VERSION ""

NS_ :

BS_:

BU_: VCU

VAL_TABLE_ RollingCounter_0x132 15 "Invalid";
VAL_TABLE_ ESC_HSA_Control_Status 1 "active" 0 "inactive";
VAL_TABLE_ ESC_HSA_Status_Fault 1 " HSA Defective" 0 "HSA Normale";
VAL_TABLE_ ESC_TcsDisableSts 3 "signal invalid" 2 "reservred" 1 "disabled" 0 "enabled";
VAL_TABLE_ ESC_TcsCtrlActv 1 "active" 0 "inactive";
VAL_TABLE_ ESC_TcsFlgFlt 1 "failure" 0 "no failure";
VAL_TABLE_ ESC_EscDisableSts 1 "disabled" 0 "enabled";
VAL_TABLE_ ESC_EscCtrlActv 1 "active" 0 "inactive";
VAL_TABLE_ ESC_EscFlgFlt 1 "failure" 0 "no failure";
VAL_TABLE_ ESC_HBAFlgFlt 1 "failure" 0 "no failure";
VAL_TABLE_ ESC_HbaCtrlActv 1 "active" 0 "inactive";
VAL_TABLE_ ESC_SlopeGradeAngle 255 "Invalid";
VAL_TABLE_ ESC_MasterCylinderPressure 4095 "Invalid";
VAL_TABLE_ RollingCounter_0x142 15 "Invalid";
VAL_TABLE_ AbsDiagSessionLampReq_Reserved 1 "lamp on" 0 "lamp off";
VAL_TABLE_ ABS_AbsCtrlActv 1 "active" 0 "inactive";
VAL_TABLE_ ABS_EbdFlgFlt 1 "failure" 0 "no failure";
VAL_TABLE_ ABS_AbsFlgFlt 1 "failure" 0 "no failure";
VAL_TABLE_ ABS_ESS_Active 1 "active" 0 "inactive";
VAL_TABLE_ ABS_LowBrakeFluid 1 "failure" 0 "no failure";
VAL_TABLE_ RollingCounter_0x332 15 "Invalid";
VAL_TABLE_ ABS_LFWhlSpdRaw 32767 "Invalid";
VAL_TABLE_ ABS_LFWhlSpdRawValid 1 "Valid" 0 "Invalid";
VAL_TABLE_ ABS_RFWhlSpdRaw 32767 "Invalid";
VAL_TABLE_ ABS_RFWhlSpdRawValid 1 "Valid" 0 "Invalid";
VAL_TABLE_ RollingCounter_0x342 15 "Invalid";
VAL_TABLE_ ABS_LRWhlSpdRaw 32767 "Invalid";
VAL_TABLE_ ABS_LRWhlSpdRawValid 1 "Valid" 0 "Invalid";
VAL_TABLE_ ABS_RRWhlSpdRaw 32767 "Invalid";
VAL_TABLE_ ABS_RRWhlSpdRawValid 1 "Valid" 0 "Invalid";
VAL_TABLE_ ABS_VehSpd 32767 "Invalid";
VAL_TABLE_ ABS_VehSpdValid 1 "Valid" 0 "Invalid";
VAL_TABLE_ RollingCounter_362 15 "Invalid";
VAL_TABLE_ ESC_RegenDragCtrlStatus 1 "active" 0 "inactive";
VAL_TABLE_ ESC_RegenBrakeCtrlStatus 1 "active" 0 "inactive";
VAL_TABLE_ ESC_TorqReqMode 3 "Reserved" 2 "Regen mode" 1 "TCS mode" 0 "Normal mode";
VAL_TABLE_ ESC_TorqRequestVal 65535 "Invalid";
VAL_TABLE_ Rolling_counter_0x37E 15 "Invalid";
VAL_TABLE_ EPS_SteeringTorque 4095 "Invalid";
VAL_TABLE_ EPS_TorqSensorStatus 1 "Invalid" 0 "Valid";
VAL_TABLE_ EPS_EpsFailed 1 "failed" 0 "not failed";
VAL_TABLE_ EPS_Mode 3 " Invalid" 1 "low assist" 0 "full assist";
VAL_TABLE_ RollingCounter_0x108 15 "Invalid";
VAL_TABLE_ EKS_DriveModeReq_reserved 1 "press" 0 "no press";
VAL_TABLE_ EKS_TargetGearReq 7 "Reserved" 4 "Invalid" 3 "D" 2 "N" 1 "R" 0 "P reserved";
VAL_TABLE_ EKS_Fault 5 "Received Date from VCU is invalid" 4 "Supply voltage failure" 3 "Position sensor failure" 2 "CAN communication fail" 1 "Shifter failure" 0 "normal";
VAL_TABLE_ RollingCounter_0x269 15 "Invalid";
VAL_TABLE_ VCU_VehicleHVStatus 3 "Reserved" 2 "ReadyToDrive" 1 "HV On" 0 "Not ready";
VAL_TABLE_ VCU_ActualGear 7 "Fault" 6 "Reserved" 5 "Reserved" 4 "Reserved" 3 "D" 2 "N" 1 "R" 0 "P reserved";
VAL_TABLE_ VCU_ActualGearValid 1 "Invalid" 0 "Valid";
VAL_TABLE_ VCU_AccPedalPosition 255 "Invalid";
VAL_TABLE_ VCU_AccPedalPositionValid 1 "Invalid" 0 "Valid";
VAL_TABLE_ VCU_TqReductionRqstResponse 1 "active" 0 "inactive";
VAL_TABLE_ VCU_BrakePedalSts 3 "Invalid" 2 "Reserved" 1 "pressed" 0 "Not pressed";
VAL_TABLE_ Rolling_Counter_0x20C 15 "Invalid";
VAL_TABLE_ IPC_ODO 1048575 "Invalid";
VAL_TABLE_ RollingCounter_0x85 15 "Invalid";
VAL_TABLE_ ACM_Crash_Sts 3 "Invalid Value" 2 "Invalid Value" 1 "Crash_Detected" 0 "No_Event";
VAL_TABLE_ ACM_Airbag_Deployment_Status 3 "Invalid Value" 2 "Invalid Value" 1 "Airbag_Deployment" 0 "No_Airbag_Deployment";
VAL_TABLE_ ACM_Crash_Intensity 7 "Invalid_Value" 6 "Invalid_Value" 5 "Invalid_Value" 4 "Invalid_Value" 3 "Crash_Intensity_3" 2 "Crash_Intensity_2" 1 "Crash_Intensity_1" 0 "No_Crash";
VAL_TABLE_ ACM_Front_Crash 3 "Invalid Value" 2 "Invalid Value" 1 "Front_Crash_Detected" 0 "No_Event";
VAL_TABLE_ ACM_DriverSide_Crash 3 "Invalid Value" 2 "Invalid Value" 1 "Driverside_Crash_Detected" 0 "No_Event";
VAL_TABLE_ ACM_PassSide_Crash 3 "Invalid Value" 2 "Invalid Value" 1 "PassSide_Crash_Detected" 0 "No_Event";
VAL_TABLE_ ACM_Rear_Crash 3 "Invalid Value" 2 "Invalid Value" 1 "Rear_Crash_Detected" 0 "No_Event";
VAL_TABLE_ ACM_Rollover_Crash 3 "Invalid Value" 2 "Invalid Value" 1 "Rollover_Crash_Detected" 0 "No_Event";
VAL_TABLE_ Rolling_Counter_0x381 15 "Invalid";
VAL_TABLE_ ACM_Seat_Occupancy_Passenger 3 "Failure" 2 "Not_Available" 1 "Seat Occupied" 0 "Seat_Not_Occupied";
VAL_TABLE_ ACM_Seat_Occupancy_2nd_Row_Dri_reserved 3 "Failure" 2 "Not_Available" 1 "Seat Occupied" 0 "Seat_Not_Occupied";
VAL_TABLE_ ACM_Seat_Occupancy_2nd_Row_Pas_reserved 3 "Failure" 2 "Not_Available" 1 "Seat Occupied" 0 "Seat_Not_Occupied";
VAL_TABLE_ ACM_Seat_Occupancy_2nd_Row_Mid_reserved 3 "Failure" 2 "Not_Available" 1 "Seat Occupied" 0 "Seat_Not_Occupied";
VAL_TABLE_ ACM_Seat_Belt_Status_Passenger 3 "Failure" 2 "Not_Available" 1 "Buckled" 0 "Not_buckled";
VAL_TABLE_ ACM_Seat_Belt_Status_Driver 3 "Failure" 2 "Not_Available" 1 "Buckled" 0 "Not_buckled";
VAL_TABLE_ ACM_Seat_Belt_Status_2nd_Row_Dri_reserved 3 "Failure" 2 "Not_Available" 1 "Buckled" 0 "Not_buckled";
VAL_TABLE_ ACM_Seat_Belt_Status_2nd_Row_Mid_reserved 3 "Failure" 2 "Not_Available" 1 "Buckled" 0 "Not_buckled";
VAL_TABLE_ ACM_Seat_Belt_Status_2nd_Row_Pas_reserved 3 "Failure" 2 "Not_Available" 1 "Buckled" 0 "Not_buckled";
VAL_TABLE_ ACM_Seat_Belt_Status_3rd_Row_Dri_reserved 3 "Failure" 2 "Not_Available" 1 "Buckled" 0 "Not_buckled";
VAL_TABLE_ ACM_Seat_Belt_Status_3rd_Row_Pas_reserved 3 "Failure" 2 "Not_Available" 1 "Buckled" 0 "Not_buckled";
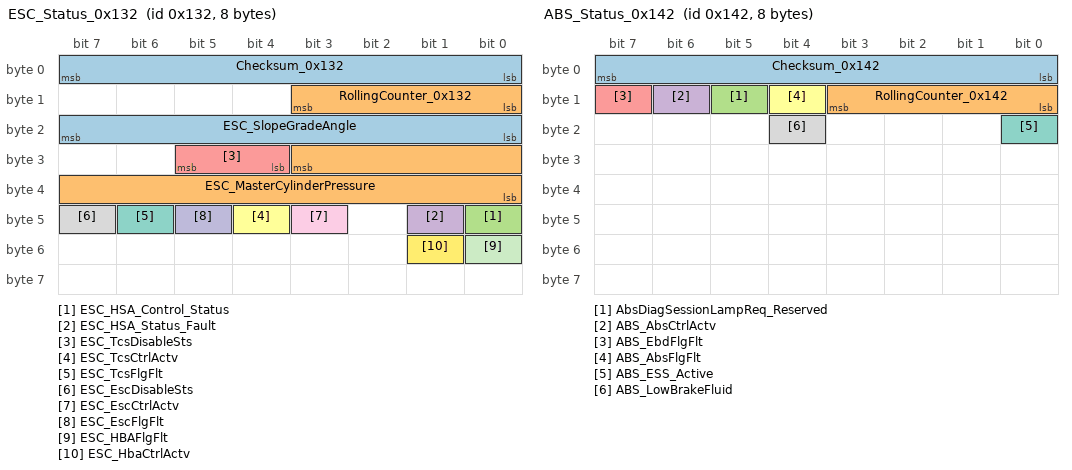
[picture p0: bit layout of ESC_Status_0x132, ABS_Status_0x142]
BO_ 306 ESC_Status_0x132: 8 Vector__XXX
 SG_ Checksum_0x132 : 7|8@0+ (1,0) [0|255] "" VCU
 SG_ RollingCounter_0x132 : 11|4@0+ (1,0) [0|15] "" VCU
 SG_ ESC_HSA_Control_Status : 40|1@0+ (1,0) [0|1] "" VCU
 SG_ ESC_HSA_Status_Fault : 41|1@0+ (1,0) [0|1] "" VCU
 SG_ ESC_TcsDisableSts : 29|2@0+ (1,0) [0|3] "" VCU
 SG_ ESC_TcsCtrlActv : 44|1@0+ (1,0) [0|1] "" VCU
 SG_ ESC_TcsFlgFlt : 46|1@0+ (1,0) [0|1] "" VCU
 SG_ ESC_EscDisableSts : 47|1@0+ (1,0) [0|1] "" VCU
 SG_ ESC_EscCtrlActv : 43|1@0+ (1,0) [0|1] "" VCU
 SG_ ESC_EscFlgFlt : 45|1@0+ (1,0) [0|1] "" VCU
 SG_ ESC_HBAFlgFlt : 48|1@0+ (1,0) [0|1] "" VCU
 SG_ ESC_HbaCtrlActv : 49|1@0+ (1,0) [0|1] "" VCU
 SG_ ESC_SlopeGradeAngle : 23|8@0+ (0.35433,-45) [-45|45] "deg" VCU
 SG_ ESC_MasterCylinderPressure : 27|12@0+ (0.1,-100) [-100|309.4] "bar" VCU
BO_ 322 ABS_Status_0x142: 8 Vector__XXX
 SG_ Checksum_0x142 : 7|8@0+ (1,0) [0|255] "" VCU
 SG_ RollingCounter_0x142 : 11|4@0+ (1,0) [0|15] "" VCU
 SG_ AbsDiagSessionLampReq_Reserved : 13|1@0+ (1,0) [0|1] "" VCU
 SG_ ABS_AbsCtrlActv : 14|1@0+ (1,0) [0|1] "" VCU
 SG_ ABS_EbdFlgFlt : 15|1@0+ (1,0) [0|1] "" VCU
 SG_ ABS_AbsFlgFlt : 12|1@0+ (1,0) [0|1] "" VCU
 SG_ ABS_ESS_Active : 16|1@0+ (1,0) [0|1] "" VCU
 SG_ ABS_LowBrakeFluid : 20|1@0+ (1,0) [0|1] "" VCU
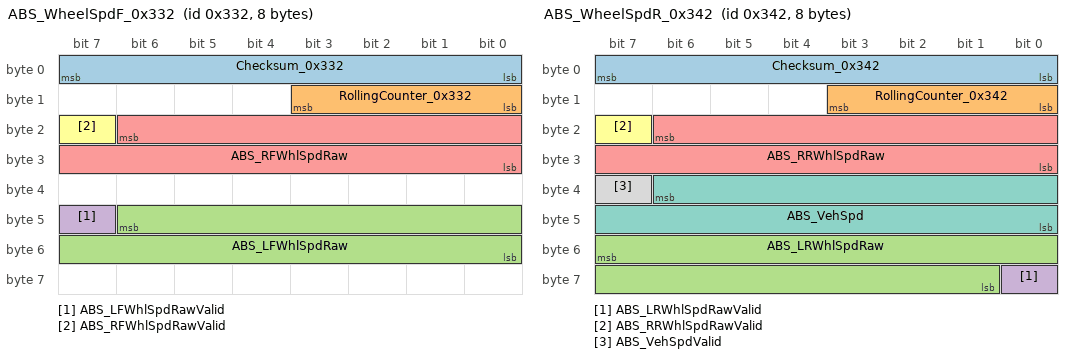
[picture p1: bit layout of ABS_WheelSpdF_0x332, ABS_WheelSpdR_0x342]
BO_ 818 ABS_WheelSpdF_0x332: 8 Vector__XXX
 SG_ Checksum_0x332 : 7|8@0+ (1,0) [0|255] "" VCU
 SG_ RollingCounter_0x332 : 11|4@0+ (1,0) [0|15] "" VCU
 SG_ ABS_LFWhlSpdRaw : 46|15@0+ (0.01,0) [0|327.66] "kph" VCU
 SG_ ABS_LFWhlSpdRawValid : 47|1@0+ (1,0) [0|1] "" VCU
 SG_ ABS_RFWhlSpdRaw : 22|15@0+ (0.01,0) [0|327.66] "kph" VCU
 SG_ ABS_RFWhlSpdRawValid : 23|1@0+ (1,0) [0|1] "" VCU
BO_ 834 ABS_WheelSpdR_0x342: 8 Vector__XXX
 SG_ Checksum_0x342 : 7|8@0+ (1,0) [0|255] "" VCU
 SG_ RollingCounter_0x342 : 11|4@0+ (1,0) [0|15] "" VCU
 SG_ ABS_LRWhlSpdRaw : 55|15@0+ (0.01,0) [0|327.66] "kph" VCU
 SG_ ABS_LRWhlSpdRawValid : 56|1@0+ (1,0) [0|1] "" VCU
 SG_ ABS_RRWhlSpdRaw : 22|15@0+ (0.01,0) [0|327.66] "kph" VCU
 SG_ ABS_RRWhlSpdRawValid : 23|1@0+ (1,0) [0|1] "" VCU
 SG_ ABS_VehSpd : 38|15@0+ (0.01,0) [0|327.66] "kph" VCU
 SG_ ABS_VehSpdValid : 39|1@0+ (1,0) [0|1] "" VCU
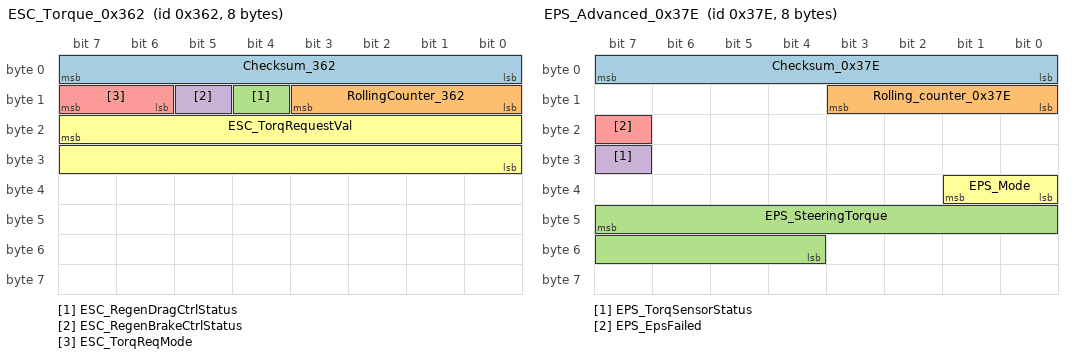
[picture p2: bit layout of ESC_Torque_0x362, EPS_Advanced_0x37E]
BO_ 866 ESC_Torque_0x362: 8 Vector__XXX
 SG_ Checksum_362 : 7|8@0+ (1,0) [0|255] "" VCU
 SG_ RollingCounter_362 : 11|4@0+ (1,0) [0|15] "" VCU
 SG_ ESC_RegenDragCtrlStatus : 12|1@0+ (1,0) [0|1] "" VCU
 SG_ ESC_RegenBrakeCtrlStatus : 13|1@0+ (1,0) [0|1] "" VCU
 SG_ ESC_TorqReqMode : 15|2@0+ (1,0) [0|3] "" VCU
 SG_ ESC_TorqRequestVal : 23|16@0+ (0.05,-1000) [-1000|1000] "Nm" VCU
BO_ 894 EPS_Advanced_0x37E: 8 Vector__XXX
 SG_ Checksum_0x37E : 7|8@0+ (1,0) [0|255] "" VCU
 SG_ Rolling_counter_0x37E : 11|4@0+ (1,0) [0|15] "" VCU
 SG_ EPS_SteeringTorque : 47|12@0+ (0.01,-20.47) [-20.47|20.47] "Nm" VCU
 SG_ EPS_TorqSensorStatus : 31|1@0+ (1,0) [0|1] "" VCU
 SG_ EPS_EpsFailed : 23|1@0+ (1,0) [0|1] "" VCU
 SG_ EPS_Mode : 33|2@0+ (1,0) [0|3] "" VCU
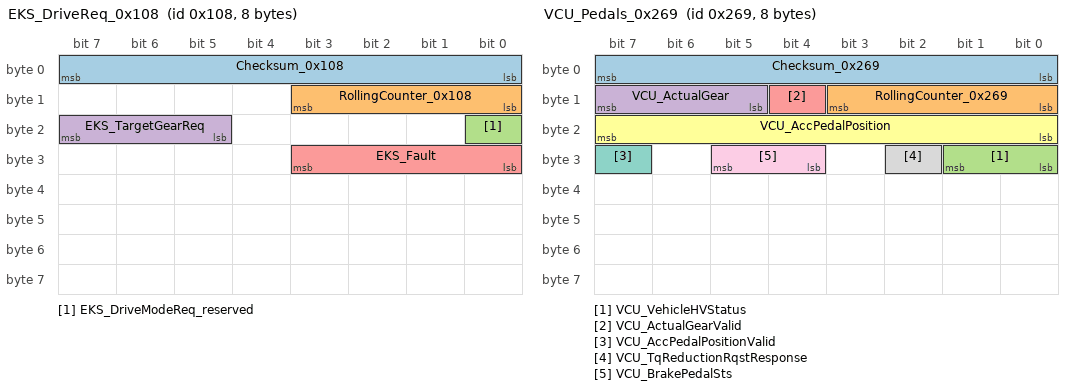
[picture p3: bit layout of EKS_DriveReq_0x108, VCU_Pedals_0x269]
BO_ 264 EKS_DriveReq_0x108: 8 Vector__XXX
 SG_ Checksum_0x108 : 7|8@0+ (1,0) [0|255] "" VCU
 SG_ RollingCounter_0x108 : 11|4@0+ (1,0) [0|15] "" VCU
 SG_ EKS_DriveModeReq_reserved : 16|1@0+ (1,0) [0|1] "" VCU
 SG_ EKS_TargetGearReq : 23|3@0+ (1,0) [0|7] "" VCU
 SG_ EKS_Fault : 27|4@0+ (1,0) [0|4] "" VCU
BO_ 617 VCU_Pedals_0x269: 8 VCU
 SG_ Checksum_0x269 : 7|8@0+ (1,0) [0|255] "" Vector__XXX
 SG_ RollingCounter_0x269 : 11|4@0+ (1,0) [0|15] "" Vector__XXX
 SG_ VCU_VehicleHVStatus : 25|2@0+ (1,0) [0|3] "" Vector__XXX
 SG_ VCU_ActualGear : 15|3@0+ (1,0) [0|7] "" Vector__XXX
 SG_ VCU_ActualGearValid : 12|1@0+ (1,0) [0|1] "" Vector__XXX
 SG_ VCU_AccPedalPosition : 23|8@0+ (0.4,0) [0|100] "%" Vector__XXX
 SG_ VCU_AccPedalPositionValid : 31|1@0+ (1,0) [0|1] "" Vector__XXX
 SG_ VCU_TqReductionRqstResponse : 26|1@0+ (1,0) [0|1] "" Vector__XXX
 SG_ VCU_BrakePedalSts : 29|2@0+ (1,0) [0|3] "" Vector__XXX
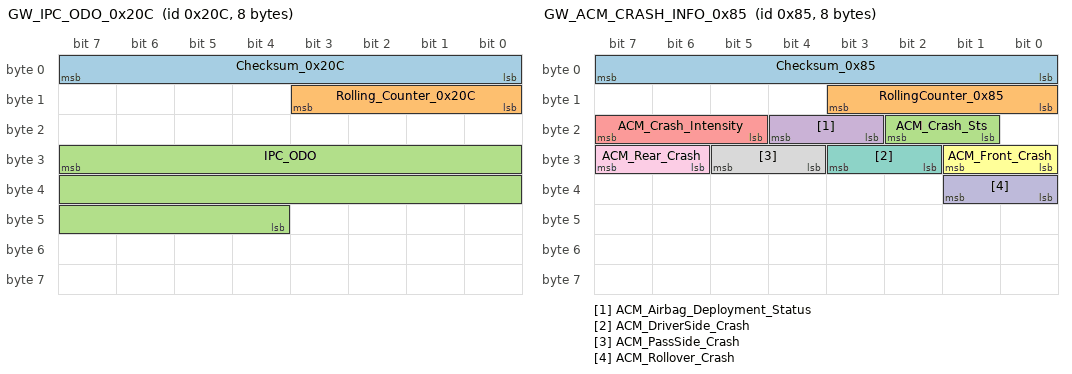
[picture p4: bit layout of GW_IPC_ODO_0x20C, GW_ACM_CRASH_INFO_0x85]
BO_ 524 GW_IPC_ODO_0x20C: 8 Vector__XXX
 SG_ Checksum_0x20C : 7|8@0+ (1,0) [0|255] "" VCU
 SG_ Rolling_Counter_0x20C : 11|4@0+ (1,0) [0|15] "" VCU
 SG_ IPC_ODO : 31|20@0+ (1,0) [0|999999] "km" VCU
BO_ 133 GW_ACM_CRASH_INFO_0x85: 8 Vector__XXX
 SG_ Checksum_0x85 : 7|8@0+ (1,0) [0|255] "" VCU
 SG_ RollingCounter_0x85 : 11|4@0+ (1,0) [0|15] "" VCU
 SG_ ACM_Crash_Sts : 18|2@0+ (1,0) [0|3] "" VCU
 SG_ ACM_Airbag_Deployment_Status : 20|2@0+ (1,0) [0|3] "" Vector__XXX
 SG_ ACM_Crash_Intensity : 23|3@0+ (1,0) [0|7] "" Vector__XXX
 SG_ ACM_Front_Crash : 25|2@0+ (1,0) [0|3] "" Vector__XXX
 SG_ ACM_DriverSide_Crash : 27|2@0+ (1,0) [0|3] "" Vector__XXX
 SG_ ACM_PassSide_Crash : 29|2@0+ (1,0) [0|3] "" Vector__XXX
 SG_ ACM_Rear_Crash : 31|2@0+ (1,0) [0|3] "" Vector__XXX
 SG_ ACM_Rollover_Crash : 33|2@0+ (1,0) [0|3] "" Vector__XXX
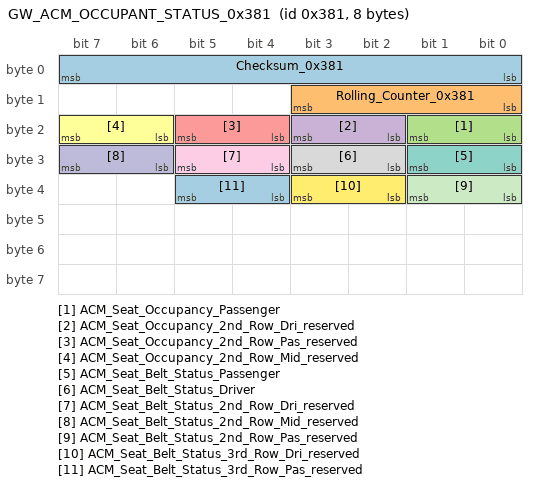
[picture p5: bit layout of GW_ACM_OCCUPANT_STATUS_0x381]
BO_ 897 GW_ACM_OCCUPANT_STATUS_0x381: 8 Vector__XXX
 SG_ Checksum_0x381 : 7|8@0+ (1,0) [0|255] "" VCU
 SG_ Rolling_Counter_0x381 : 11|4@0+ (1,0) [0|15] "" VCU
 SG_ ACM_Seat_Occupancy_Passenger : 17|2@0+ (1,0) [0|3] "" VCU
 SG_ ACM_Seat_Occupancy_2nd_Row_Dri_reserved : 19|2@0+ (1,0) [0|3] "" VCU
 SG_ ACM_Seat_Occupancy_2nd_Row_Pas_reserved : 21|2@0+ (1,0) [0|3] "" VCU
 SG_ ACM_Seat_Occupancy_2nd_Row_Mid_reserved : 23|2@0+ (1,0) [0|3] "" VCU
 SG_ ACM_Seat_Belt_Status_Passenger : 25|2@0+ (1,0) [0|3] "" VCU
 SG_ ACM_Seat_Belt_Status_Driver : 27|2@0+ (1,0) [0|3] "" VCU
 SG_ ACM_Seat_Belt_Status_2nd_Row_Dri_reserved : 29|2@0+ (1,0) [0|3] "" VCU
 SG_ ACM_Seat_Belt_Status_2nd_Row_Mid_reserved : 31|2@0+ (1,0) [0|3] "" VCU
 SG_ ACM_Seat_Belt_Status_2nd_Row_Pas_reserved : 33|2@0+ (1,0) [0|3] "" VCU
 SG_ ACM_Seat_Belt_Status_3rd_Row_Dri_reserved : 35|2@0+ (1,0) [0|3] "" VCU
 SG_ ACM_Seat_Belt_Status_3rd_Row_Pas_reserved : 37|2@0+ (1,0) [0|3] "" VCU
CM_ SG_ 306 Checksum_0x132 "check sum";
CM_ SG_ 306 RollingCounter_0x132 "Rolling counter";
CM_ SG_ 306 ESC_HSA_Control_Status "Indicate HSA function is active or not";
CM_ SG_ 306 ESC_HSA_Status_Fault "Detect the HAS Fault status";
CM_ SG_ 306 ESC_TcsDisableSts "Indicate the TCS function can use or not";
CM_ SG_ 306 ESC_TcsCtrlActv "Indicate TCS  function is active or not";
CM_ SG_ 306 ESC_TcsFlgFlt "Detect the TCS function fault status";
CM_ SG_ 306 ESC_EscDisableSts "Indicate the ESC function can use or not";
CM_ SG_ 306 ESC_EscCtrlActv "Indicate ESC  function is active or not";
CM_ SG_ 306 ESC_EscFlgFlt "Detect the ESC function fault status";
CM_ SG_ 306 ESC_HBAFlgFlt "Detect the HBA(Hydraulic Brake Assist) function status";
CM_ SG_ 306 ESC_HbaCtrlActv "Indicate HBA(Hydraulic Brake Assist)   function is active or not";
CM_ SG_ 306 ESC_SlopeGradeAngle "Vehicle slope,Uphill is negative (head is higher than tail), downhill is positive (tail is higher than head)";
CM_ SG_ 306 ESC_MasterCylinderPressure "Master cylinder pressure";
CM_ SG_ 322 Checksum_0x142 "check sum";
CM_ SG_ 322 RollingCounter_0x142 "Rolling counter";
CM_ SG_ 322 AbsDiagSessionLampReq_Reserved "ABS or ESC is currently in safety system diagnostic  session,(DVT mode) need cluster to turn on ESC/TCS, EBD, ABS fault lamp";
CM_ SG_ 322 ABS_AbsCtrlActv "ABS status(Indiacte ABS  function is active or not.When ABS intervention starts,it sets as 1)";
CM_ SG_ 322 ABS_EbdFlgFlt "The EBD system fault, The EBD warning lamp should be open,The signal will be set as  whenEBD is disable due to fault";
CM_ SG_ 322 ABS_AbsFlgFlt "The ABS system fault, The ABS warning lamp should be open,The signal will be set as whenABS is disable due to fault";
CM_ SG_ 322 ABS_ESS_Active "Emergency Stop Signaling Active,when emergency stop, this signal will set true";
CM_ SG_ 322 ABS_LowBrakeFluid "Detect the brake fluid level";
CM_ SG_ 818 Checksum_0x332 "check sum";
CM_ SG_ 818 RollingCounter_0x332 "Rolling counter";
CM_ SG_ 818 ABS_LFWhlSpdRaw "Current Raw wheel speed information of front left wheel.";
CM_ SG_ 818 ABS_LFWhlSpdRawValid "Current Raw wheel speed information valid flag of front left wheel.";
CM_ SG_ 818 ABS_RFWhlSpdRaw "Current Raw wheel speed information of front right wheel.";
CM_ SG_ 818 ABS_RFWhlSpdRawValid "Current Raw wheel speed information valid flag of front right wheel.";
CM_ SG_ 834 Checksum_0x342 "Check sum";
CM_ SG_ 834 RollingCounter_0x342 "Rolling Counter";
CM_ SG_ 834 ABS_LRWhlSpdRaw "Current Raw wheel speed information of rear left wheel.";
CM_ SG_ 834 ABS_LRWhlSpdRawValid "Current Raw wheel speed information valid flag of rear left wheel.";
CM_ SG_ 834 ABS_RRWhlSpdRaw "Current Raw wheel speed information of rear right wheel.,";
CM_ SG_ 834 ABS_RRWhlSpdRawValid "Current Raw wheel speed information valid flag of rear right wheel";
CM_ SG_ 834 ABS_VehSpd "Current Longitudinal Vehicle Speed";
CM_ SG_ 834 ABS_VehSpdValid "Speed Valid Flag";
CM_ SG_ 866 Checksum_362 "check sum";
CM_ SG_ 866 RollingCounter_362 "Rolling counter";
CM_ SG_ 866 ESC_RegenDragCtrlStatus "Indicate RDC  function is active or not";
CM_ SG_ 866 ESC_RegenBrakeCtrlStatus "Indicate RBC  function is active or not";
CM_ SG_ 866 ESC_TorqReqMode "Indicate the torque request mode";
CM_ SG_ 866 ESC_TorqRequestVal "Regen torque request and TCS torque request(in motor torque domain)";
CM_ SG_ 894 Checksum_0x37E "Check sum";
CM_ SG_ 894 Rolling_counter_0x37E "Rolling Counter";
CM_ SG_ 894 EPS_SteeringTorque "steering torque bosch(Positive, to left; Negative, to right)";
CM_ SG_ 894 EPS_TorqSensorStatus "Validation bit of torsion bar torque";
CM_ SG_ 894 EPS_EpsFailed "EPS failed bit";
CM_ SG_ 894 EPS_Mode "Electric steering mode";
CM_ SG_ 264 Checksum_0x108 "Check sum";
CM_ SG_ 264 RollingCounter_0x108 "Rolling Counter";
CM_ SG_ 264 EKS_DriveModeReq_reserved "The drive mode request";
CM_ SG_ 264 EKS_TargetGearReq "Target gear request";
CM_ SG_ 264 EKS_Fault "Fault statue";
CM_ SG_ 617 Checksum_0x269 "Check sum";
CM_ SG_ 617 RollingCounter_0x269 "Rolling counter";
CM_ SG_ 617 VCU_VehicleHVStatus "Vehicle High voltage Ready State";
CM_ SG_ 617 VCU_ActualGear "actual gear,Provide gear shift signal";
CM_ SG_ 617 VCU_ActualGearValid "Indicate the current gear position Valid";
CM_ SG_ 617 VCU_AccPedalPosition "Indicate the acceleraton pedal position";
CM_ SG_ 617 VCU_AccPedalPositionValid "Indicate the acceleration pedal position valid flag";
CM_ SG_ 617 VCU_TqReductionRqstResponse "Indicate the response for the RBS/TCS request torqueRBS/TCS";
CM_ SG_ 617 VCU_BrakePedalSts "Brake Pedal Sts";
CM_ SG_ 524 Checksum_0x20C "Checksum";
CM_ SG_ 524 Rolling_Counter_0x20C "Rolling_Counter";
CM_ SG_ 524 IPC_ODO "odograph";
CM_ SG_ 133 Checksum_0x85 "Check sum";
CM_ SG_ 133 RollingCounter_0x85 "Rolling counter";
CM_ SG_ 133 ACM_Crash_Sts "Crash status";
CM_ SG_ 133 ACM_Airbag_Deployment_Status "Signal to indicate if airbag/pretensioner/pyrofuse is deployed";
CM_ SG_ 133 ACM_Crash_Intensity "Indicate crash intensity level";
CM_ SG_ 133 ACM_Front_Crash "Output information for direction of crash";
CM_ SG_ 133 ACM_DriverSide_Crash "Output information for direction of crash";
CM_ SG_ 133 ACM_PassSide_Crash "Output information for direction of crash";
CM_ SG_ 133 ACM_Rear_Crash "Output information for direction of crash";
CM_ SG_ 133 ACM_Rollover_Crash "Output information for direction of crash";
CM_ SG_ 897 Checksum_0x381 "Checksum";
CM_ SG_ 897 Rolling_Counter_0x381 "Rolling Counter";
CM_ SG_ 897 ACM_Seat_Occupancy_Passenger "Signal to indicate status of occupancy";
CM_ SG_ 897 ACM_Seat_Occupancy_2nd_Row_Dri_reserved "Signal to indicate status of occupancy";
CM_ SG_ 897 ACM_Seat_Occupancy_2nd_Row_Pas_reserved "Signal to indicate status of occupancy";
CM_ SG_ 897 ACM_Seat_Occupancy_2nd_Row_Mid_reserved "Signal to indicate status of occupancy";
CM_ SG_ 897 ACM_Seat_Belt_Status_Passenger "Seatbelt status for seatbelt reminder function";
CM_ SG_ 897 ACM_Seat_Belt_Status_Driver "Seatbelt status for seatbelt reminder function";
CM_ SG_ 897 ACM_Seat_Belt_Status_2nd_Row_Dri_reserved "Seatbelt status for seatbelt reminder function";
CM_ SG_ 897 ACM_Seat_Belt_Status_2nd_Row_Mid_reserved "Seatbelt status for seatbelt reminder function";
CM_ SG_ 897 ACM_Seat_Belt_Status_2nd_Row_Pas_reserved "Seatbelt status for seatbelt reminder function";
CM_ SG_ 897 ACM_Seat_Belt_Status_3rd_Row_Dri_reserved "Seatbelt status for seatbelt reminder function";
CM_ SG_ 897 ACM_Seat_Belt_Status_3rd_Row_Pas_reserved "Seatbelt status for seatbelt reminder function";
BA_DEF_ BO_ "GenMsgCycleTime" INT 0 65535;
BA_DEF_ BO_ "GenMsgCycleTimeFast" INT 0 65535;
BA_DEF_ BO_ "GenMsgDelayTime" INT 0 65535;
BA_DEF_ BO_ "GenMsgILSupport" ENUM "No","Yes";
BA_DEF_ BO_ "GenMsgNrOfRepetition" INT 0 65535;
BA_DEF_ BO_ "GenMsgSendType" ENUM  "Cycle","Event","IfActive","CE","CA";
BA_DEF_ SG_ "GenSigSendType" ENUM  "Cycle","OnWrite","OnWriteWithRepetition","OnChange","OnChangeWithRepetition","IfActive","IfActiveWithRepetition";
BA_DEF_ SG_ "GenSigStartValue" INT 0 2147483647;
BA_DEF_ SG_ "GenSigInvalidValue" INT 0 2147483647;
BA_DEF_ SG_ "GenSigInactiveValue" INT 0 2147483647;
BA_DEF_ BU_ "ILUsed" ENUM  "No","Yes";
BA_DEF_ BU_ "NmAsrCanMsgReducedTime" INT 320 640;
BA_DEF_  "Baudrate" INT 0 1000000;
BA_DEF_  "BusType" STRING;
BA_DEF_  "Manufacturer" STRING;
BA_DEF_  "NmAsrBaseAddress" HEX 0 2047;
BA_DEF_  "NmAsrCanMsgCycleTime" INT 0 65535;
BA_DEF_  "NmAsrMessageCount" INT 1 256;
BA_DEF_  "NmAsrRepeatMessageTime" INT 0 65535;
BA_DEF_  "NmAsrTimeoutTime" INT 0 65535;
BA_DEF_  "NmAsrWaitBusSleepTime" INT 0 65535;
BA_DEF_  "NmType" STRING;
BA_DEF_DEF_ "Baudrate" 500000;
BA_DEF_DEF_ "BusType" "CAN";
BA_DEF_DEF_ "GenMsgCycleTime" 0;
BA_DEF_DEF_ "GenMsgCycleTimeFast" 0;
BA_DEF_DEF_ "GenMsgDelayTime" 0;
BA_DEF_DEF_ "GenMsgILSupport" "Yes";
BA_DEF_DEF_ "GenMsgNrOfRepetition" 0;
BA_DEF_DEF_ "GenMsgSendType" "NoMsgSendType";
BA_DEF_DEF_ "GenSigSendType" "NoSigSendType";
BA_DEF_DEF_ "GenSigStartValue" 0;
BA_DEF_DEF_  "GenSigInvalidValue" 0;
BA_DEF_DEF_ "GenSigInactiveValue" 0;
BA_DEF_DEF_ "ILUsed" "Yes";
BA_DEF_DEF_ "Manufacturer" "Launch";
BA_DEF_DEF_ "NmAsrBaseAddress" 1280;
BA_DEF_DEF_ "NmAsrCanMsgCycleTime" 640;
BA_DEF_DEF_ "NmAsrCanMsgReducedTime" 320;
BA_DEF_DEF_ "NmAsrMessageCount" 128;
BA_DEF_DEF_ "NmAsrRepeatMessageTime" 3200;
BA_DEF_DEF_ "NmAsrTimeoutTime" 2000;
BA_DEF_DEF_ "NmAsrWaitBusSleepTime" 1500;
BA_DEF_DEF_ "NmType" "NmAsr";

BA_ "GenMsgSendType" BO_ 306 0;
BA_ "GenMsgCycleTime" BO_ 306 20;
BA_ "GenMsgSendType" BO_ 322 0;
BA_ "GenMsgCycleTime" BO_ 322 20;
BA_ "GenMsgSendType" BO_ 818 0;
BA_ "GenMsgCycleTime" BO_ 818 10;
BA_ "GenMsgSendType" BO_ 834 0;
BA_ "GenMsgCycleTime" BO_ 834 10;
BA_ "GenMsgSendType" BO_ 866 0;
BA_ "GenMsgCycleTime" BO_ 866 20;
BA_ "GenMsgSendType" BO_ 894 0;
BA_ "GenMsgCycleTime" BO_ 894 20;
BA_ "GenMsgSendType" BO_ 264 0;
BA_ "GenMsgCycleTime" BO_ 264 50;
BA_ "GenMsgSendType" BO_ 617 0;
BA_ "GenMsgCycleTime" BO_ 617 20;
BA_ "GenMsgSendType" BO_ 524 0;
BA_ "GenMsgCycleTime" BO_ 524 100;
BA_ "GenMsgSendType" BO_ 133 0;
BA_ "GenMsgCycleTime" BO_ 133 20;
BA_ "GenMsgSendType" BO_ 897 0;
BA_ "GenMsgCycleTime" BO_ 897 200;
BA_ "GenSigSendType" SG_ 306 Checksum_0x132 0;
BA_ "GenSigSendType" SG_ 306 RollingCounter_0x132 0;
BA_ "GenSigInvalidValue" SG_ 306 RollingCounter_0x132 15;
BA_ "GenSigSendType" SG_ 306 ESC_HSA_Control_Status 0;
BA_ "GenSigSendType" SG_ 306 ESC_HSA_Status_Fault 0;
BA_ "GenSigSendType" SG_ 306 ESC_TcsDisableSts 0;
BA_ "GenSigInvalidValue" SG_ 306 ESC_TcsDisableSts 3;
BA_ "GenSigSendType" SG_ 306 ESC_TcsCtrlActv 0;
BA_ "GenSigSendType" SG_ 306 ESC_TcsFlgFlt 0;
BA_ "GenSigSendType" SG_ 306 ESC_EscDisableSts 0;
BA_ "GenSigSendType" SG_ 306 ESC_EscCtrlActv 0;
BA_ "GenSigSendType" SG_ 306 ESC_EscFlgFlt 0;
BA_ "GenSigSendType" SG_ 306 ESC_HBAFlgFlt 0;
BA_ "GenSigSendType" SG_ 306 ESC_HbaCtrlActv 0;
BA_ "GenSigSendType" SG_ 306 ESC_SlopeGradeAngle 0;
BA_ "GenSigInvalidValue" SG_ 306 ESC_SlopeGradeAngle 255;
BA_ "GenSigSendType" SG_ 306 ESC_MasterCylinderPressure 0;
BA_ "GenSigInvalidValue" SG_ 306 ESC_MasterCylinderPressure 4095;
BA_ "GenSigStartValue" SG_ 306 ESC_MasterCylinderPressure 1000;
BA_ "GenSigSendType" SG_ 322 Checksum_0x142 0;
BA_ "GenSigSendType" SG_ 322 RollingCounter_0x142 0;
BA_ "GenSigInvalidValue" SG_ 322 RollingCounter_0x142 15;
BA_ "GenSigSendType" SG_ 322 AbsDiagSessionLampReq_Reserved 0;
BA_ "GenSigSendType" SG_ 322 ABS_AbsCtrlActv 0;
BA_ "GenSigSendType" SG_ 322 ABS_EbdFlgFlt 0;
BA_ "GenSigSendType" SG_ 322 ABS_AbsFlgFlt 0;
BA_ "GenSigSendType" SG_ 322 ABS_ESS_Active 0;
BA_ "GenSigSendType" SG_ 322 ABS_LowBrakeFluid 0;
BA_ "GenSigSendType" SG_ 818 Checksum_0x332 0;
BA_ "GenSigSendType" SG_ 818 RollingCounter_0x332 0;
BA_ "GenSigInvalidValue" SG_ 818 RollingCounter_0x332 15;
BA_ "GenSigSendType" SG_ 818 ABS_LFWhlSpdRaw 0;
BA_ "GenSigInvalidValue" SG_ 818 ABS_LFWhlSpdRaw 32767;
BA_ "GenSigSendType" SG_ 818 ABS_LFWhlSpdRawValid 0;
BA_ "GenSigSendType" SG_ 818 ABS_RFWhlSpdRaw 0;
BA_ "GenSigInvalidValue" SG_ 818 ABS_RFWhlSpdRaw 32767;
BA_ "GenSigSendType" SG_ 818 ABS_RFWhlSpdRawValid 0;
BA_ "GenSigSendType" SG_ 834 Checksum_0x342 0;
BA_ "GenSigSendType" SG_ 834 RollingCounter_0x342 0;
BA_ "GenSigInvalidValue" SG_ 834 RollingCounter_0x342 15;
BA_ "GenSigSendType" SG_ 834 ABS_LRWhlSpdRaw 0;
BA_ "GenSigInvalidValue" SG_ 834 ABS_LRWhlSpdRaw 32767;
BA_ "GenSigSendType" SG_ 834 ABS_LRWhlSpdRawValid 0;
BA_ "GenSigSendType" SG_ 834 ABS_RRWhlSpdRaw 0;
BA_ "GenSigInvalidValue" SG_ 834 ABS_RRWhlSpdRaw 32767;
BA_ "GenSigSendType" SG_ 834 ABS_RRWhlSpdRawValid 0;
BA_ "GenSigSendType" SG_ 834 ABS_VehSpd 0;
BA_ "GenSigInvalidValue" SG_ 834 ABS_VehSpd 32767;
BA_ "GenSigSendType" SG_ 834 ABS_VehSpdValid 0;
BA_ "GenSigSendType" SG_ 866 Checksum_362 0;
BA_ "GenSigSendType" SG_ 866 RollingCounter_362 0;
BA_ "GenSigInvalidValue" SG_ 866 RollingCounter_362 15;
BA_ "GenSigSendType" SG_ 866 ESC_RegenDragCtrlStatus 0;
BA_ "GenSigSendType" SG_ 866 ESC_RegenBrakeCtrlStatus 0;
BA_ "GenSigSendType" SG_ 866 ESC_TorqReqMode 0;
BA_ "GenSigSendType" SG_ 866 ESC_TorqRequestVal 0;
BA_ "GenSigInvalidValue" SG_ 866 ESC_TorqRequestVal 65535;
BA_ "GenSigSendType" SG_ 894 Checksum_0x37E 0;
BA_ "GenSigSendType" SG_ 894 Rolling_counter_0x37E 0;
BA_ "GenSigInvalidValue" SG_ 894 Rolling_counter_0x37E 15;
BA_ "GenSigSendType" SG_ 894 EPS_SteeringTorque 0;
BA_ "GenSigInvalidValue" SG_ 894 EPS_SteeringTorque 4095;
BA_ "GenSigSendType" SG_ 894 EPS_TorqSensorStatus 0;
BA_ "GenSigInvalidValue" SG_ 894 EPS_TorqSensorStatus 1;
BA_ "GenSigSendType" SG_ 894 EPS_EpsFailed 0;
BA_ "GenSigInvalidValue" SG_ 894 EPS_EpsFailed 1;
BA_ "GenSigStartValue" SG_ 894 EPS_EpsFailed 1;
BA_ "GenSigSendType" SG_ 894 EPS_Mode 0;
BA_ "GenSigInvalidValue" SG_ 894 EPS_Mode 3;
BA_ "GenSigSendType" SG_ 264 Checksum_0x108 0;
BA_ "GenSigSendType" SG_ 264 RollingCounter_0x108 0;
BA_ "GenSigInvalidValue" SG_ 264 RollingCounter_0x108 15;
BA_ "GenSigSendType" SG_ 264 EKS_DriveModeReq_reserved 0;
BA_ "GenSigSendType" SG_ 264 EKS_TargetGearReq 0;
BA_ "GenSigInvalidValue" SG_ 264 EKS_TargetGearReq 4;
BA_ "GenSigSendType" SG_ 264 EKS_Fault 0;
BA_ "GenSigSendType" SG_ 617 Checksum_0x269 0;
BA_ "GenSigSendType" SG_ 617 RollingCounter_0x269 0;
BA_ "GenSigInvalidValue" SG_ 617 RollingCounter_0x269 15;
BA_ "GenSigSendType" SG_ 617 VCU_VehicleHVStatus 0;
BA_ "GenSigInvalidValue" SG_ 617 VCU_VehicleHVStatus 3;
BA_ "GenSigSendType" SG_ 617 VCU_ActualGear 0;
BA_ "GenSigInvalidValue" SG_ 617 VCU_ActualGear 7;
BA_ "GenSigStartValue" SG_ 617 VCU_ActualGear 2;
BA_ "GenSigSendType" SG_ 617 VCU_ActualGearValid 0;
BA_ "GenSigInvalidValue" SG_ 617 VCU_ActualGearValid 1;
BA_ "GenSigSendType" SG_ 617 VCU_AccPedalPosition 0;
BA_ "GenSigInvalidValue" SG_ 617 VCU_AccPedalPosition 255;
BA_ "GenSigSendType" SG_ 617 VCU_AccPedalPositionValid 0;
BA_ "GenSigInvalidValue" SG_ 617 VCU_AccPedalPositionValid 1;
BA_ "GenSigSendType" SG_ 617 VCU_TqReductionRqstResponse 0;
BA_ "GenSigStartValue" SG_ 617 VCU_TqReductionRqstResponse 1;
BA_ "GenSigSendType" SG_ 617 VCU_BrakePedalSts 0;
BA_ "GenSigInvalidValue" SG_ 617 VCU_BrakePedalSts 3;
BA_ "GenSigSendType" SG_ 524 Checksum_0x20C 0;
BA_ "GenSigSendType" SG_ 524 Rolling_Counter_0x20C 0;
BA_ "GenSigInvalidValue" SG_ 524 Rolling_Counter_0x20C 15;
BA_ "GenSigSendType" SG_ 524 IPC_ODO 0;
BA_ "GenSigInvalidValue" SG_ 524 IPC_ODO 1048575;
BA_ "GenSigSendType" SG_ 133 Checksum_0x85 0;
BA_ "GenSigSendType" SG_ 133 RollingCounter_0x85 0;
BA_ "GenSigInvalidValue" SG_ 133 RollingCounter_0x85 15;
BA_ "GenSigSendType" SG_ 133 ACM_Crash_Sts 0;
BA_ "GenSigSendType" SG_ 133 ACM_Airbag_Deployment_Status 0;
BA_ "GenSigSendType" SG_ 133 ACM_Crash_Intensity 0;
BA_ "GenSigSendType" SG_ 133 ACM_Front_Crash 0;
BA_ "GenSigSendType" SG_ 133 ACM_DriverSide_Crash 0;
BA_ "GenSigSendType" SG_ 133 ACM_PassSide_Crash 0;
BA_ "GenSigSendType" SG_ 133 ACM_Rear_Crash 0;
BA_ "GenSigSendType" SG_ 133 ACM_Rollover_Crash 0;
BA_ "GenSigSendType" SG_ 897 Checksum_0x381 0;
BA_ "GenSigSendType" SG_ 897 Rolling_Counter_0x381 0;
BA_ "GenSigInvalidValue" SG_ 897 Rolling_Counter_0x381 15;
BA_ "GenSigSendType" SG_ 897 ACM_Seat_Occupancy_Passenger 0;
BA_ "GenSigStartValue" SG_ 897 ACM_Seat_Occupancy_Passenger 2;
BA_ "GenSigSendType" SG_ 897 ACM_Seat_Occupancy_2nd_Row_Dri_reserved 0;
BA_ "GenSigStartValue" SG_ 897 ACM_Seat_Occupancy_2nd_Row_Dri_reserved 2;
BA_ "GenSigSendType" SG_ 897 ACM_Seat_Occupancy_2nd_Row_Pas_reserved 0;
BA_ "GenSigStartValue" SG_ 897 ACM_Seat_Occupancy_2nd_Row_Pas_reserved 2;
BA_ "GenSigSendType" SG_ 897 ACM_Seat_Occupancy_2nd_Row_Mid_reserved 0;
BA_ "GenSigStartValue" SG_ 897 ACM_Seat_Occupancy_2nd_Row_Mid_reserved 2;
BA_ "GenSigSendType" SG_ 897 ACM_Seat_Belt_Status_Passenger 0;
BA_ "GenSigSendType" SG_ 897 ACM_Seat_Belt_Status_Driver 0;
BA_ "GenSigSendType" SG_ 897 ACM_Seat_Belt_Status_2nd_Row_Dri_reserved 0;
BA_ "GenSigSendType" SG_ 897 ACM_Seat_Belt_Status_2nd_Row_Mid_reserved 0;
BA_ "GenSigSendType" SG_ 897 ACM_Seat_Belt_Status_2nd_Row_Pas_reserved 0;
BA_ "GenSigSendType" SG_ 897 ACM_Seat_Belt_Status_3rd_Row_Dri_reserved 0;
BA_ "GenSigStartValue" SG_ 897 ACM_Seat_Belt_Status_3rd_Row_Dri_reserved 2;
BA_ "GenSigSendType" SG_ 897 ACM_Seat_Belt_Status_3rd_Row_Pas_reserved 0;
BA_ "GenSigStartValue" SG_ 897 ACM_Seat_Belt_Status_3rd_Row_Pas_reserved 2;
VAL_ 306 RollingCounter_0x132 15 "Invalid";
VAL_ 306 ESC_HSA_Control_Status 1 "active" 0 "inactive";
VAL_ 306 ESC_HSA_Status_Fault 1 " HSA Defective" 0 "HSA Normale";
VAL_ 306 ESC_TcsDisableSts 3 "signal invalid" 2 "reservred" 1 "disabled" 0 "enabled";
VAL_ 306 ESC_TcsCtrlActv 1 "active" 0 "inactive";
VAL_ 306 ESC_TcsFlgFlt 1 "failure" 0 "no failure";
VAL_ 306 ESC_EscDisableSts 1 "disabled" 0 "enabled";
VAL_ 306 ESC_EscCtrlActv 1 "active" 0 "inactive";
VAL_ 306 ESC_EscFlgFlt 1 "failure" 0 "no failure";
VAL_ 306 ESC_HBAFlgFlt 1 "failure" 0 "no failure";
VAL_ 306 ESC_HbaCtrlActv 1 "active" 0 "inactive";
VAL_ 306 ESC_SlopeGradeAngle 255 "Invalid";
VAL_ 306 ESC_MasterCylinderPressure 4095 "Invalid";
VAL_ 322 RollingCounter_0x142 15 "Invalid";
VAL_ 322 AbsDiagSessionLampReq_Reserved 1 "lamp on" 0 "lamp off";
VAL_ 322 ABS_AbsCtrlActv 1 "active" 0 "inactive";
VAL_ 322 ABS_EbdFlgFlt 1 "failure" 0 "no failure";
VAL_ 322 ABS_AbsFlgFlt 1 "failure" 0 "no failure";
VAL_ 322 ABS_ESS_Active 1 "active" 0 "inactive";
VAL_ 322 ABS_LowBrakeFluid 1 "failure" 0 "no failure";
VAL_ 818 RollingCounter_0x332 15 "Invalid";
VAL_ 818 ABS_LFWhlSpdRaw 32767 "Invalid";
VAL_ 818 ABS_LFWhlSpdRawValid 1 "Valid" 0 "Invalid";
VAL_ 818 ABS_RFWhlSpdRaw 32767 "Invalid";
VAL_ 818 ABS_RFWhlSpdRawValid 1 "Valid" 0 "Invalid";
VAL_ 834 RollingCounter_0x342 15 "Invalid";
VAL_ 834 ABS_LRWhlSpdRaw 32767 "Invalid";
VAL_ 834 ABS_LRWhlSpdRawValid 1 "Valid" 0 "Invalid";
VAL_ 834 ABS_RRWhlSpdRaw 32767 "Invalid";
VAL_ 834 ABS_RRWhlSpdRawValid 1 "Valid" 0 "Invalid";
VAL_ 834 ABS_VehSpd 32767 "Invalid";
VAL_ 834 ABS_VehSpdValid 1 "Valid" 0 "Invalid";
VAL_ 866 RollingCounter_362 15 "Invalid";
VAL_ 866 ESC_RegenDragCtrlStatus 1 "active" 0 "inactive";
VAL_ 866 ESC_RegenBrakeCtrlStatus 1 "active" 0 "inactive";
VAL_ 866 ESC_TorqReqMode 3 "Reserved" 2 "Regen mode" 1 "TCS mode" 0 "Normal mode";
VAL_ 866 ESC_TorqRequestVal 65535 "Invalid";
VAL_ 894 Rolling_counter_0x37E 15 "Invalid";
VAL_ 894 EPS_SteeringTorque 4095 "Invalid";
VAL_ 894 EPS_TorqSensorStatus 1 "Invalid" 0 "Valid";
VAL_ 894 EPS_EpsFailed 1 "failed" 0 "not failed";
VAL_ 894 EPS_Mode 3 " Invalid" 1 "low assist" 0 "full assist";
VAL_ 264 RollingCounter_0x108 15 "Invalid";
VAL_ 264 EKS_DriveModeReq_reserved 1 "press" 0 "no press";
VAL_ 264 EKS_TargetGearReq 7 "Reserved" 4 "Invalid" 3 "D" 2 "N" 1 "R" 0 "P reserved";
VAL_ 264 EKS_Fault 5 "Received Date from VCU is invalid" 4 "Supply voltage failure" 3 "Position sensor failure" 2 "CAN communication fail" 1 "Shifter failure" 0 "normal";
VAL_ 617 RollingCounter_0x269 15 "Invalid";
VAL_ 617 VCU_VehicleHVStatus 3 "Reserved" 2 "ReadyToDrive" 1 "HV On" 0 "Not ready";
VAL_ 617 VCU_ActualGear 7 "Fault" 6 "Reserved" 5 "Reserved" 4 "Reserved" 3 "D" 2 "N" 1 "R" 0 "P reserved";
VAL_ 617 VCU_ActualGearValid 1 "Invalid" 0 "Valid";
VAL_ 617 VCU_AccPedalPosition 255 "Invalid";
VAL_ 617 VCU_AccPedalPositionValid 1 "Invalid" 0 "Valid";
VAL_ 617 VCU_TqReductionRqstResponse 1 "active" 0 "inactive";
VAL_ 617 VCU_BrakePedalSts 3 "Invalid" 2 "Reserved" 1 "pressed" 0 "Not pressed";
VAL_ 524 Rolling_Counter_0x20C 15 "Invalid";
VAL_ 524 IPC_ODO 1048575 "Invalid";
VAL_ 133 RollingCounter_0x85 15 "Invalid";
VAL_ 133 ACM_Crash_Sts 3 "Invalid Value" 2 "Invalid Value" 1 "Crash_Detected" 0 "No_Event";
VAL_ 133 ACM_Airbag_Deployment_Status 3 "Invalid Value" 2 "Invalid Value" 1 "Airbag_Deployment" 0 "No_Airbag_Deployment";
VAL_ 133 ACM_Crash_Intensity 7 "Invalid_Value" 6 "Invalid_Value" 5 "Invalid_Value" 4 "Invalid_Value" 3 "Crash_Intensity_3" 2 "Crash_Intensity_2" 1 "Crash_Intensity_1" 0 "No_Crash";
VAL_ 133 ACM_Front_Crash 3 "Invalid Value" 2 "Invalid Value" 1 "Front_Crash_Detected" 0 "No_Event";
VAL_ 133 ACM_DriverSide_Crash 3 "Invalid Value" 2 "Invalid Value" 1 "Driverside_Crash_Detected" 0 "No_Event";
VAL_ 133 ACM_PassSide_Crash 3 "Invalid Value" 2 "Invalid Value" 1 "PassSide_Crash_Detected" 0 "No_Event";
VAL_ 133 ACM_Rear_Crash 3 "Invalid Value" 2 "Invalid Value" 1 "Rear_Crash_Detected" 0 "No_Event";
VAL_ 133 ACM_Rollover_Crash 3 "Invalid Value" 2 "Invalid Value" 1 "Rollover_Crash_Detected" 0 "No_Event";
VAL_ 897 Rolling_Counter_0x381 15 "Invalid";
VAL_ 897 ACM_Seat_Occupancy_Passenger 3 "Failure" 2 "Not_Available" 1 "Seat Occupied" 0 "Seat_Not_Occupied";
VAL_ 897 ACM_Seat_Occupancy_2nd_Row_Dri_reserved 3 "Failure" 2 "Not_Available" 1 "Seat Occupied" 0 "Seat_Not_Occupied";
VAL_ 897 ACM_Seat_Occupancy_2nd_Row_Pas_reserved 3 "Failure" 2 "Not_Available" 1 "Seat Occupied" 0 "Seat_Not_Occupied";
VAL_ 897 ACM_Seat_Occupancy_2nd_Row_Mid_reserved 3 "Failure" 2 "Not_Available" 1 "Seat Occupied" 0 "Seat_Not_Occupied";
VAL_ 897 ACM_Seat_Belt_Status_Passenger 3 "Failure" 2 "Not_Available" 1 "Buckled" 0 "Not_buckled";
VAL_ 897 ACM_Seat_Belt_Status_Driver 3 "Failure" 2 "Not_Available" 1 "Buckled" 0 "Not_buckled";
VAL_ 897 ACM_Seat_Belt_Status_2nd_Row_Dri_reserved 3 "Failure" 2 "Not_Available" 1 "Buckled" 0 "Not_buckled";
VAL_ 897 ACM_Seat_Belt_Status_2nd_Row_Mid_reserved 3 "Failure" 2 "Not_Available" 1 "Buckled" 0 "Not_buckled";
VAL_ 897 ACM_Seat_Belt_Status_2nd_Row_Pas_reserved 3 "Failure" 2 "Not_Available" 1 "Buckled" 0 "Not_buckled";
VAL_ 897 ACM_Seat_Belt_Status_3rd_Row_Dri_reserved 3 "Failure" 2 "Not_Available" 1 "Buckled" 0 "Not_buckled";
VAL_ 897 ACM_Seat_Belt_Status_3rd_Row_Pas_reserved 3 "Failure" 2 "Not_Available" 1 "Buckled" 0 "Not_buckled";
